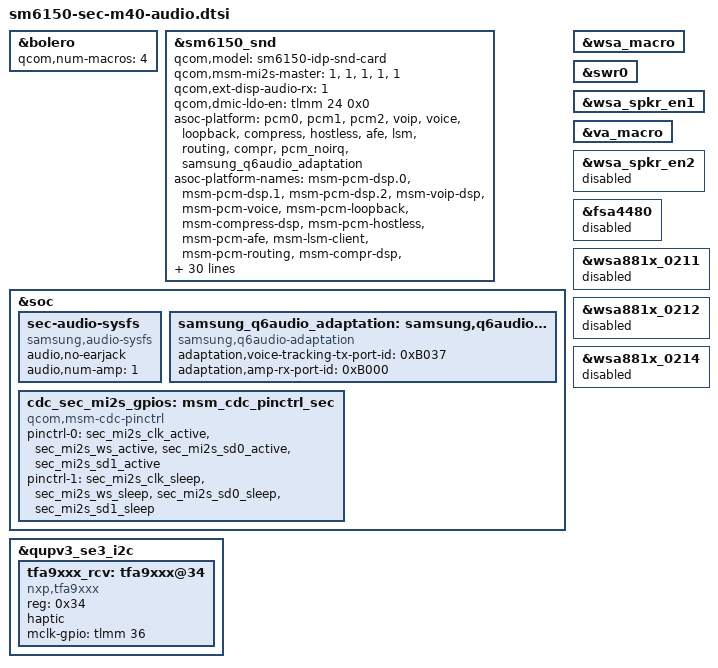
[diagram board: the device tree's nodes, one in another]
/* Copyright (c) 2018, The Linux Foundation. All rights reserved.
 *
 * This program is free software; you can redistribute it and/or modify
 * it under the terms of the GNU General Public License version 2 and
 * only version 2 as published by the Free Software Foundation.
 *
 * This program is distributed in the hope that it will be useful,
 * but WITHOUT ANY WARRANTY; without even the implied warranty of
 * MERCHANTABILITY or FITNESS FOR A PARTICULAR PURPOSE.  See the
 * GNU General Public License for more details.
 */

#include "../qcom/sm6150-audio-overlay.dtsi"

&bolero {
	qcom,num-macros = <4>;
};

&sm6150_snd {
	qcom,model = "sm6150-idp-snd-card";
	qcom,msm-mi2s-master = <1>, <1>, <1>, <1>, <1>;
	qcom,ext-disp-audio-rx = <1>;
	qcom,dmic-ldo-en = <&tlmm 24 0x0>;

	asoc-platform = <&pcm0>, <&pcm1>, <&pcm2>, <&voip>, <&voice>,
			<&loopback>, <&compress>, <&hostless>,
			<&afe>, <&lsm>, <&routing>, <&compr>,
			<&pcm_noirq>, <&samsung_q6audio_adaptation>;
	asoc-platform-names = "msm-pcm-dsp.0", "msm-pcm-dsp.1",
			"msm-pcm-dsp.2", "msm-voip-dsp",
			"msm-pcm-voice", "msm-pcm-loopback",
			"msm-compress-dsp", "msm-pcm-hostless",
			"msm-pcm-afe", "msm-lsm-client",
			"msm-pcm-routing", "msm-compr-dsp",
			"msm-pcm-dsp-noirq", "q6audio-adaptation";
	qcom,audio-routing =
		"TX DMIC0", "Digital Mic0",
		"TX DMIC1", "Digital Mic1",
		"TX DMIC2", "Digital Mic2",
		"TX_AIF1 CAP", "VA_MCLK",
		"TX_AIF2 CAP", "VA_MCLK",
		"RX AIF1 PB", "VA_MCLK",
		"RX AIF2 PB", "VA_MCLK",
		"RX AIF3 PB", "VA_MCLK",
		"RX AIF4 PB", "VA_MCLK",
		"IN1_HPHL", "HPHL_OUT",
		"IN2_HPHR", "HPHR_OUT",
		"IN3_AUX", "AUX_OUT",
		"TX SWR_ADC0", "ADC1_OUTPUT",
		"TX SWR_ADC2", "ADC2_OUTPUT",
		"WSA SRC0_INP", "SRC0",
		"WSA_TX DEC0_INP", "TX DEC0 MUX",
		"WSA_TX DEC1_INP", "TX DEC1 MUX",
		"RX_TX DEC0_INP", "TX DEC0 MUX",
		"RX_TX DEC1_INP", "TX DEC1 MUX",
		"RX_TX DEC2_INP", "TX DEC2 MUX",
		"RX_TX DEC3_INP", "TX DEC3 MUX",
		"SpkrLeft IN", "WSA_SPK1 OUT";
	qcom,msm-mbhc-hphl-swh = <0>;
	qcom,msm-mbhc-gnd-swh = <0>;
        qcom,fm-lna-gpios = <&tlmm 119 0>;
	asoc-codec  = <&stub_codec>, <&bolero>, <&ext_disp_audio_codec>;
	asoc-codec-names = "msm-stub-codec.1", "bolero_codec",
			   "msm-ext-disp-audio-codec-rx";
	qcom,wsa-max-devs = <1>;
	qcom,wsa-devs = <&wsa881x_0213>;
	qcom,wsa-aux-dev-prefix = "SpkrLeft";
	qcom,codec-max-aux-devs = <0>;
	qcom,msm_audio_ssr_devs = <&audio_apr>, <&q6core>,
				<&lpi_tlmm>, <&bolero>;
	qcom,sec-mi2s-gpios = <&cdc_sec_mi2s_gpios>;
};

&soc {
	sec-audio-sysfs {
		compatible = "samsung,audio-sysfs";
		status = "okay";
		audio,no-earjack;
		audio,num-amp = <1>;
	};
	samsung_q6audio_adaptation: samsung,q6audio-adaptation {
		compatible = "samsung,q6audio-adaptation";
		adaptation,voice-tracking-tx-port-id = <0xB037>;
		adaptation,amp-rx-port-id = <0xB000>;
	};

	cdc_sec_mi2s_gpios: msm_cdc_pinctrl_sec {
		compatible = "qcom,msm-cdc-pinctrl";
		pinctrl-names = "aud_active", "aud_sleep";
		pinctrl-0 = <&sec_mi2s_clk_active &sec_mi2s_ws_active
				 &sec_mi2s_sd0_active &sec_mi2s_sd1_active>;
		pinctrl-1 = <&sec_mi2s_clk_sleep &sec_mi2s_ws_sleep
				 &sec_mi2s_sd0_sleep &sec_mi2s_sd1_sleep>;
	};
};

&qupv3_se3_i2c {
	status = "ok";
	tfa9xxx_rcv: tfa9xxx@34 {
		compatible = "nxp,tfa9xxx";
		reg = <0x34>;
		haptic; /* this device has the LRA */
		mclk-gpio = <&tlmm 36 0x00>;		
	};
};

&wsa_macro {
	status = "okay";
};
&swr0 {
	status = "okay";
};
&wsa_spkr_en1 {
	status = "okay";
};

&va_macro {
	status = "okay";
};
&wsa_spkr_en2 {
	status = "disabled";
};
&fsa4480 {
	status = "disabled";
};
&wsa881x_0211 {
	status = "disabled";
};
&wsa881x_0212 {
	status = "disabled";
};
&wsa881x_0214 {
	status = "disabled";
};
